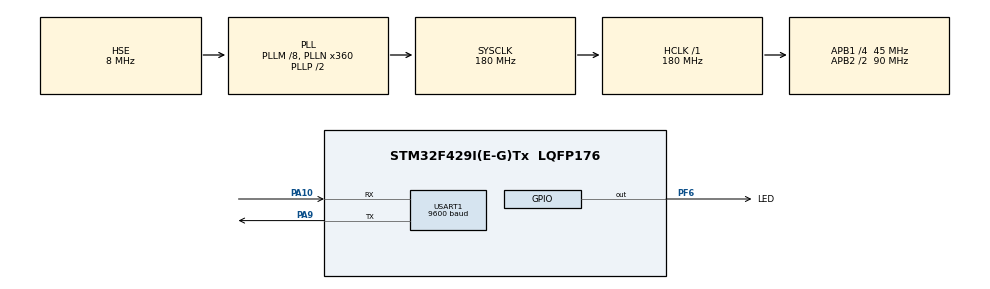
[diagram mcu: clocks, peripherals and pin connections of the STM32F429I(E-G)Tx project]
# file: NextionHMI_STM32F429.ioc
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Mcu.Family=STM32F4
Mcu.Name=STM32F429I(E-G)Tx
Mcu.Package=LQFP176
NVIC.PriorityGroup=NVIC_PRIORITYGROUP_4
NVIC.TIM7_IRQn=true\:0\:0\:false\:false\:true\:false
NVIC.TimeBase=TIM7_IRQn
NVIC.TimeBaseIP=TIM7
NVIC.USART1_IRQn=true\:0\:0\:false\:false\:true\:true
PA10.Mode=Asynchronous
PA10.Signal=USART1_RX
PA13.Mode=JTAG_5_pins
PA13.Signal=SYS_JTMS-SWDIO
PA14.Mode=JTAG_5_pins
PA14.Signal=SYS_JTCK-SWCLK
PA15.Mode=JTAG_5_pins
PA15.Signal=SYS_JTDI
PA9.Mode=Asynchronous
PA9.Signal=USART1_TX
PB3.Mode=JTAG_5_pins
PB3.Signal=SYS_JTDO-SWO
PB4.Mode=JTAG_5_pins
PB4.Signal=SYS_JTRST
PF6.GPIO_Label=LED
PF6.Signal=GPIO_Output
PH0/OSC_IN.Mode=HSE-External-Oscillator
PH0/OSC_IN.Signal=RCC_OSC_IN
PH1/OSC_OUT.Mode=HSE-External-Oscillator
PH1/OSC_OUT.Signal=RCC_OSC_OUT
ProjectManager.HeapSize=0x200
ProjectManager.StackSize=0x400
ProjectManager.TargetToolchain=SW4STM32
RCC.48MHZClocksFreq_Value=90000000
RCC.AHBFreq_Value=180000000
RCC.APB1CLKDivider=RCC_HCLK_DIV4
RCC.APB1Freq_Value=45000000
RCC.APB1TimFreq_Value=90000000
RCC.APB2CLKDivider=RCC_HCLK_DIV2
RCC.APB2Freq_Value=90000000
RCC.APB2TimFreq_Value=180000000
RCC.CortexFreq_Value=180000000
RCC.HCLKFreq_Value=180000000
RCC.HSE_VALUE=8000000
RCC.HSI_VALUE=16000000
RCC.LSE_VALUE=32768
RCC.PLLM=8
RCC.PLLN=360
RCC.PLLSourceVirtual=RCC_PLLSOURCE_HSE
RCC.SYSCLKFreq_VALUE=180000000
RCC.SYSCLKSource=RCC_SYSCLKSOURCE_PLLCLK
RCC.VCOOutputFreq_Value=360000000
USART1.BaudRate=9600
USART1.VirtualMode=VM_ASYNC
VP_SYS_VS_tim7.Mode=TIM7
board=custom

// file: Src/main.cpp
/* USER CODE BEGIN Header */
/**
  ******************************************************************************
  * @file           : main.c
  * @brief          : Main program body
  ******************************************************************************
  ** This notice applies to any and all portions of this file
  * that are not between comment pairs USER CODE BEGIN and
  * USER CODE END. Other portions of this file, whether
  * inserted by the user or by software development tools
  * are owned by their respective copyright owners.
  *
  * COPYRIGHT(c) 2019 STMicroelectronics
  *
  * Redistribution and use in source and binary forms, with or without modification,
  * are permitted provided that the following conditions are met:
  *   1. Redistributions of source code must retain the above copyright notice,
  *      this list of conditions and the following disclaimer.
  *   2. Redistributions in binary form must reproduce the above copyright notice,
  *      this list of conditions and the following disclaimer in the documentation
  *      and/or other materials provided with the distribution.
  *   3. Neither the name of STMicroelectronics nor the names of its contributors
  *      may be used to endorse or promote products derived from this software
  *      without specific prior written permission.
  *
  * THIS SOFTWARE IS PROVIDED BY THE COPYRIGHT HOLDERS AND CONTRIBUTORS "AS IS"
  * AND ANY EXPRESS OR IMPLIED WARRANTIES, INCLUDING, BUT NOT LIMITED TO, THE
  * IMPLIED WARRANTIES OF MERCHANTABILITY AND FITNESS FOR A PARTICULAR PURPOSE ARE
  * DISCLAIMED. IN NO EVENT SHALL THE COPYRIGHT HOLDER OR CONTRIBUTORS BE LIABLE
  * FOR ANY DIRECT, INDIRECT, INCIDENTAL, SPECIAL, EXEMPLARY, OR CONSEQUENTIAL
  * DAMAGES (INCLUDING, BUT NOT LIMITED TO, PROCUREMENT OF SUBSTITUTE GOODS OR
  * SERVICES; LOSS OF USE, DATA, OR PROFITS; OR BUSINESS INTERRUPTION) HOWEVER
  * CAUSED AND ON ANY THEORY OF LIABILITY, WHETHER IN CONTRACT, STRICT LIABILITY,
  * OR TORT (INCLUDING NEGLIGENCE OR OTHERWISE) ARISING IN ANY WAY OUT OF THE USE
  * OF THIS SOFTWARE, EVEN IF ADVISED OF THE POSSIBILITY OF SUCH DAMAGE.
  *
  ******************************************************************************
  */
/* USER CODE END Header */

#include "main.h"

/* USER CODE BEGIN Includes */

#include <doxygen.h>
#include "NexButton.h"
#include <NexConfig.h>
#include <NexCrop.h>
#include <NexDualStateButton.h>
#include <NexGauge.h>
#include <NexGpio.h>
#include <NexHardware.h>
#include <NexHotspot.h>
#include <NexNumber.h>
#include <NexObject.h>
#include <NexPage.h>
#include <NexPicture.h>
#include <NexProgressBar.h>
#include <NexRadio.h>
#include <NexRtc.h>
#include <NexScrolltext.h>
#include <NexSlider.h>
#include <NexText.h>
#include <NexTimer.h>
#include <Nextion.h>
#include <NexTouch.h>
#include <NexVariable.h>
#include <NexWaveform.h>
#include <Serial.h>
#include "string.h"

/* USER CODE END Includes */

UART_HandleTypeDef huart1;

/* USER CODE BEGIN PV */

Serial* serial;

NexText tStatus = NexText(0, 8, "tStatus");
NexText tMessage = NexText(0, 5, "tMessage");
NexText tMinute = NexText(0, 1, "tMinute");
NexText tSecond = NexText(0, 3, "tSecond");
NexButton bStart = NexButton(0, 6, "bStart");
NexButton bStop = NexButton(0, 7, "bStop");

NexTouch *nex_listen_list[] = {
  &bStart,
  &bStop
};

/* USER CODE END PV */

void SystemClock_Config(void);
static void MX_GPIO_Init(void);
static void MX_USART1_UART_Init(void);

/* USER CODE BEGIN 0 */

//Usart RX Interrupt
void HAL_UART_RxCpltCallback(UART_HandleTypeDef *huart)
{
	if (huart->Instance == USART1)
	{
		if (serial != NULL)
		{
			serial->put(huart->Instance->DR);
		}
	}
}

void bOnPopCallback(void *ptr) {
  tStatus.setText("Islem baslatildi.");
  HAL_GPIO_WritePin(LED_GPIO_Port,LED_Pin,GPIO_PIN_SET);
}

void bOffPopCallback(void *ptr) {
  tStatus.setText("Islem sonlandirildi.");
  HAL_GPIO_WritePin(LED_GPIO_Port,LED_Pin,GPIO_PIN_RESET);
}

/* USER CODE END 0 */

int main(void)
{

  /* MCU Configuration--------------------------------------------------------*/

  /* Reset of all peripherals, Initializes the Flash interface and the Systick. */
  HAL_Init();

  /* Configure the system clock */
  SystemClock_Config();

  /* Initialize all configured peripherals */
  MX_GPIO_Init();
  MX_USART1_UART_Init();
  /* USER CODE BEGIN 2 */

  serial = new Serial(&huart1,64);

  nexInit(serial);

  bStart.attachPop(bOnPopCallback, &bStart);
  bStop.attachPop(bOffPopCallback, &bStop);

  /* USER CODE END 2 */

  /* Infinite loop */
  while (1)
  {
	nexLoop(nex_listen_list);

	/*
	if (serial->available()) {
		HAL_GPIO_WritePin(LED_GPIO_Port,LED_Pin,GPIO_PIN_SET);
		HAL_Delay(100);

		uint8_t x = serial->read();

		uint8_t data[10];

		memset(data,0,10);

		serial->readBytes(data,9);

		if (strcmp((char*) data,"123456789") == 0) {
			serial->write(50);
			serial->print("Test");
			serial->println();
			serial->println("TEST");
		}
	}
	else {
		HAL_GPIO_WritePin(LED_GPIO_Port,LED_Pin,GPIO_PIN_RESET);
	}
	*/
  }
}

void SystemClock_Config(void)
{
  RCC_OscInitTypeDef RCC_OscInitStruct = {0};
  RCC_ClkInitTypeDef RCC_ClkInitStruct = {0};

  /**Configure the main internal regulator output voltage
  */
  __HAL_RCC_PWR_CLK_ENABLE();
  __HAL_PWR_VOLTAGESCALING_CONFIG(PWR_REGULATOR_VOLTAGE_SCALE1);
  /**Initializes the CPU, AHB and APB busses clocks
  */
  RCC_OscInitStruct.OscillatorType = RCC_OSCILLATORTYPE_HSE;
  RCC_OscInitStruct.HSEState = RCC_HSE_ON;
  RCC_OscInitStruct.PLL.PLLState = RCC_PLL_ON;
  RCC_OscInitStruct.PLL.PLLSource = RCC_PLLSOURCE_HSE;
  RCC_OscInitStruct.PLL.PLLM = 8;
  RCC_OscInitStruct.PLL.PLLN = 360;
  RCC_OscInitStruct.PLL.PLLP = RCC_PLLP_DIV2;
  RCC_OscInitStruct.PLL.PLLQ = 4;
  if (HAL_RCC_OscConfig(&RCC_OscInitStruct) != HAL_OK)
  {
    Error_Handler();
  }
  /**Activate the Over-Drive mode
  */
  if (HAL_PWREx_EnableOverDrive() != HAL_OK)
  {
    Error_Handler();
  }
  /**Initializes the CPU, AHB and APB busses clocks
  */
  RCC_ClkInitStruct.ClockType = RCC_CLOCKTYPE_HCLK|RCC_CLOCKTYPE_SYSCLK
                              |RCC_CLOCKTYPE_PCLK1|RCC_CLOCKTYPE_PCLK2;
  RCC_ClkInitStruct.SYSCLKSource = RCC_SYSCLKSOURCE_PLLCLK;
  RCC_ClkInitStruct.AHBCLKDivider = RCC_SYSCLK_DIV1;
  RCC_ClkInitStruct.APB1CLKDivider = RCC_HCLK_DIV4;
  RCC_ClkInitStruct.APB2CLKDivider = RCC_HCLK_DIV2;

  if (HAL_RCC_ClockConfig(&RCC_ClkInitStruct, FLASH_LATENCY_5) != HAL_OK)
  {
    Error_Handler();
  }
}

static void MX_USART1_UART_Init(void)
{

  huart1.Instance = USART1;
  huart1.Init.BaudRate = 9600;
  huart1.Init.WordLength = UART_WORDLENGTH_8B;
  huart1.Init.StopBits = UART_STOPBITS_1;
  huart1.Init.Parity = UART_PARITY_NONE;
  huart1.Init.Mode = UART_MODE_TX_RX;
  huart1.Init.HwFlowCtl = UART_HWCONTROL_NONE;
  huart1.Init.OverSampling = UART_OVERSAMPLING_16;
  if (HAL_UART_Init(&huart1) != HAL_OK)
  {
    Error_Handler();
  }

}

static void MX_GPIO_Init(void)
{
  GPIO_InitTypeDef GPIO_InitStruct = {0};

  /* GPIO Ports Clock Enable */
  __HAL_RCC_GPIOF_CLK_ENABLE();
  __HAL_RCC_GPIOH_CLK_ENABLE();
  __HAL_RCC_GPIOA_CLK_ENABLE();
  __HAL_RCC_GPIOB_CLK_ENABLE();

  /*Configure GPIO pin Output Level */
  HAL_GPIO_WritePin(LED_GPIO_Port, LED_Pin, GPIO_PIN_RESET);

  /*Configure GPIO pin : LED_Pin */
  GPIO_InitStruct.Pin = LED_Pin;
  GPIO_InitStruct.Mode = GPIO_MODE_OUTPUT_PP;
  GPIO_InitStruct.Pull = GPIO_NOPULL;
  GPIO_InitStruct.Speed = GPIO_SPEED_FREQ_LOW;
  HAL_GPIO_Init(LED_GPIO_Port, &GPIO_InitStruct);

}

void HAL_TIM_PeriodElapsedCallback(TIM_HandleTypeDef *htim)
{
  if (htim->Instance == TIM7) {
    HAL_IncTick();
  }
}

void Error_Handler(void)
{
}

/************************ (C) COPYRIGHT STMicroelectronics *****END OF FILE****/
